# f28p551x_adc_regs register map
Vendor: Texas Instruments
Peripheral module from a debugger description file (folder C2000).
Address unit: 16 bits
Registers are 16-bit, read-write, no defined reset value unless marked. A register's access mark holds for its fields unless they carry their own. Offsets are as the file gives them; lines under a group give offsets from that group; [hi:lo] are bit positions; {n}, {i} and the like mark numbered series; 'fields as' and 'values as' point back to an identical list; <NAME> marks a mode.

## ADC_REGS — ADC Registers
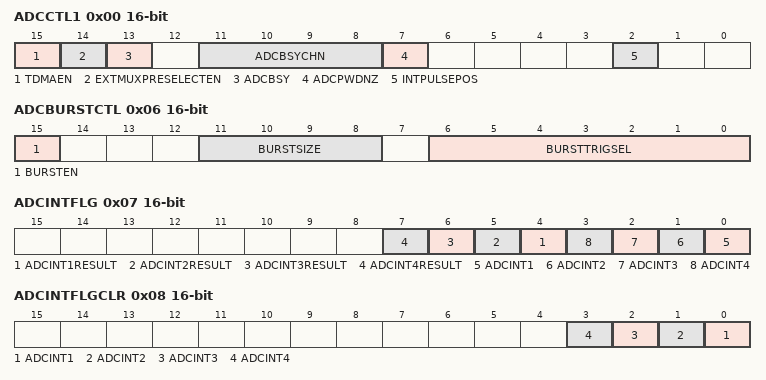
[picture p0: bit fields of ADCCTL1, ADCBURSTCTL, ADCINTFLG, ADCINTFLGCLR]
0x00 ADCCTL1 access per field — ADC Control 1 Register
  [15] TDMAEN rw — Enable Alternate DMA Timings
  [14] EXTMUXPRESELECTEN rw — External Mux Preselect Enable
  [13] ADCBSY ro — ADC Busy
  [11:8] ADCBSYCHN ro — ADC Busy Channel
  [7] ADCPWDNZ rw — ADC Power Down
  [2] INTPULSEPOS rw — ADC Interrupt Pulse Position
0x01 ADCCTL2 — ADC Control 2 Register
  [3:0] PRESCALE — ADC Clock Prescaler
0x06 ADCBURSTCTL — ADC Burst Control Register
  [15] BURSTEN — SOC Burst Mode Enable
  [11:8] BURSTSIZE — SOC Burst Size Select
  [6:0] BURSTTRIGSEL — SOC Burst Trigger Source Select
0x07 ADCINTFLG ro — ADC Interrupt Flag Register
  [n+3] ADCINT{n}RESULT (n=1..4) — ADC Interrupt {n} Results Ready
  [n-1] ADCINT{n} (n=1..4) — ADC Interrupt {n} Flag
0x08 ADCINTFLGCLR — ADC Interrupt Flag Clear Register
  [n-1] ADCINT{n} (n=1..4) — ADC Interrupt {n} Flag Clear
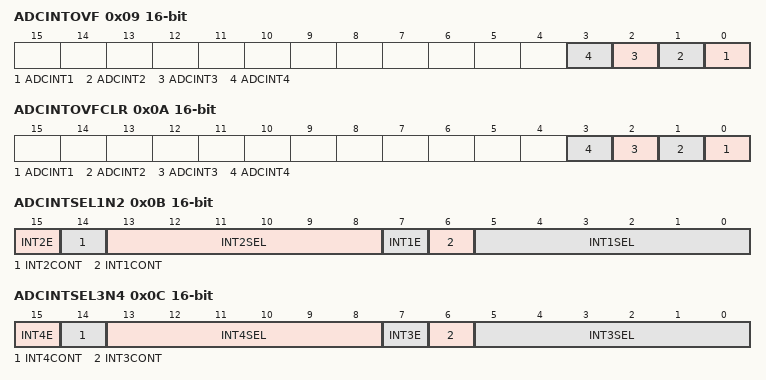
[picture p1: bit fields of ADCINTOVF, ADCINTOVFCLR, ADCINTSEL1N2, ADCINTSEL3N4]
0x09 ADCINTOVF ro — ADC Interrupt Overflow Register
  [n-1] ADCINT{n} (n=1..4) — ADC Interrupt {n} Overflow Flags
0x0A ADCINTOVFCLR — ADC Interrupt Overflow Clear Register
  [n-1] ADCINT{n} (n=1..4) — ADC Interrupt {n} Overflow Clear Bits
0x0B ADCINTSEL1N2 — ADC Interrupt 1 and 2 Selection Register
  [15] INT2E — ADCINT2 Interrupt Enable
  [14] INT2CONT — ADCINT2 Continue to Interrupt Mode
  [13:8] INT2SEL — ADCINT2 EOC Source Select
  [7] INT1E — ADCINT1 Interrupt Enable
  [6] INT1CONT — ADCINT1 Continue to Interrupt Mode
  [5:0] INT1SEL — ADCINT1 EOC Source Select
0x0C ADCINTSEL3N4 — ADC Interrupt 3 and 4 Selection Register
  [15] INT4E — ADCINT4 Interrupt Enable
  [14] INT4CONT — ADCINT4 Continue to Interrupt Mode
  [13:8] INT4SEL — ADCINT4 EOC Source Select
  [7] INT3E — ADCINT3 Interrupt Enable
  [6] INT3CONT — ADCINT3 Continue to Interrupt Mode
  [5:0] INT3SEL — ADCINT3 EOC Source Select
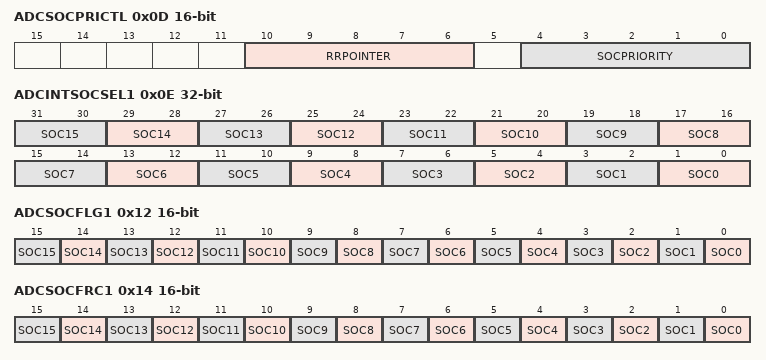
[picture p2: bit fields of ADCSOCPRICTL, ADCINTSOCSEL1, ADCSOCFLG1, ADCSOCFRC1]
0x0D ADCSOCPRICTL access per field — ADC SOC Priority Control Register
  [10:6] RRPOINTER ro — Round Robin Pointer
  [4:0] SOCPRIORITY rw
0x0E ADCINTSOCSEL1 32-bit — ADC Interrupt SOC Selection 1 Register
  [2n+1:2n] SOC{n} (n=0..15) — SOC{n} ADC Interrupt Trigger Select
0x12 ADCSOCFLG1 ro — ADC SOC Flag 1 Register
  [n] SOC{n} (n=0..15) — SOC{n} Start of Conversion Flag
0x14 ADCSOCFRC1 — ADC SOC Force 1 Register
  [n] SOC{n} (n=0..15) — SOC{n} Force Start of Conversion Bit
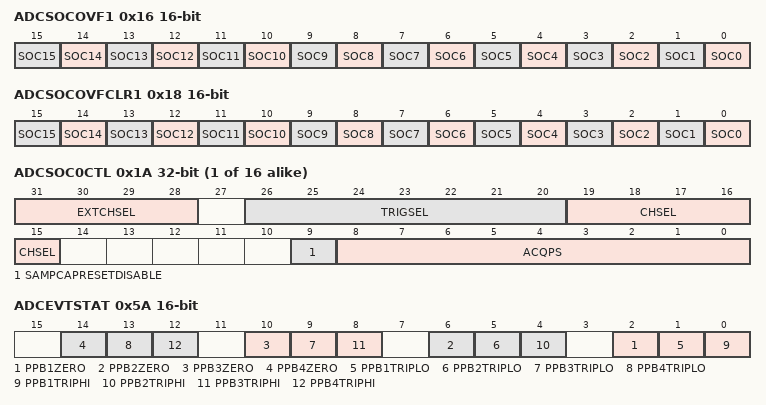
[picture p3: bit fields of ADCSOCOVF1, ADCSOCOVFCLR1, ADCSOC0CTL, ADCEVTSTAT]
0x16 ADCSOCOVF1 ro — ADC SOC Overflow 1 Register
  [n] SOC{n} (n=0..15) — SOC{n} Start of Conversion Overflow Flag
0x18 ADCSOCOVFCLR1 — ADC SOC Overflow Clear 1 Register
  [n] SOC{n} (n=0..15) — SOC{n} Clear Start of Conversion Overflow Bit
{0x1A+2i} ADCSOC{i}CTL 32-bit (i=0..15) — ADC SOC{i} Control Register
  [31:28] EXTCHSEL — SOC{i} External Channel Mux Select
  [26:20] TRIGSEL — SOC{i} Trigger Source Select
  [19:15] CHSEL — SOC{i} Channel Select
  [9] SAMPCAPRESETDISABLE — SOC{i} Sample Cap Reset Select
  [8:0] ACQPS — SOC{i} Acquisition Prescale
0x5A ADCEVTSTAT ro — ADC Event Status Register
  [4n-2] PPB{n}ZERO (n=1..4) — Post Processing Block {n} Zero Crossing Flag
  [4n-3] PPB{n}TRIPLO (n=1..4) — Post Processing Block {n} Trip Low Flag
  [4n-4] PPB{n}TRIPHI (n=1..4) — Post Processing Block {n} Trip High Flag
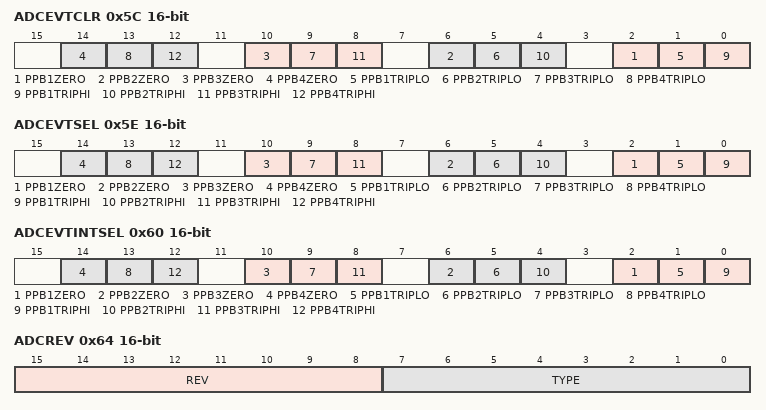
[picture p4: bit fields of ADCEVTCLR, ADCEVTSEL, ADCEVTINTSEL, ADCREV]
0x5C ADCEVTCLR — ADC Event Clear Register
  [4n-2] PPB{n}ZERO (n=1..4) — Post Processing Block {n} Zero Crossing Clear
  [4n-3] PPB{n}TRIPLO (n=1..4) — Post Processing Block {n} Trip Low Clear
  [4n-4] PPB{n}TRIPHI (n=1..4) — Post Processing Block {n} Trip High Clear
0x5E ADCEVTSEL — ADC Event Selection Register
  [4n-2] PPB{n}ZERO (n=1..4) — Post Processing Block {n} Zero Crossing Event Enable
  [4n-3] PPB{n}TRIPLO (n=1..4) — Post Processing Block {n} Trip Low Event Enable
  [4n-4] PPB{n}TRIPHI (n=1..4) — Post Processing Block {n} Trip High Event Enable
0x60 ADCEVTINTSEL — ADC Event Interrupt Selection Register
  [4n-2] PPB{n}ZERO (n=1..4) — Post Processing Block {n} Zero Crossing Interrupt Enable
  [4n-3] PPB{n}TRIPLO (n=1..4) — Post Processing Block {n} Trip Low Interrupt Enable
  [4n-4] PPB{n}TRIPHI (n=1..4) — Post Processing Block {n} Trip High Interrupt Enable
0x63 ADCCOUNTER ro
  [11:0] FREECOUNT — ADC Free Running Counter Value
0x64 ADCREV ro — ADC Revision Register
  [15:8] REV — ADC Revision
  [7:0] TYPE — ADC Type
0x65 ADCOFFTRIM — ADC Offset Trim Register
  [11:0] OFFTRIM — ADC Offset Trim
0x66 ADCCONFIG2 32-bit — ADC Config Register Upper 32 bits
  [1:0] TESTANA1_CONFIG — TESTANA1 ADC Configuration
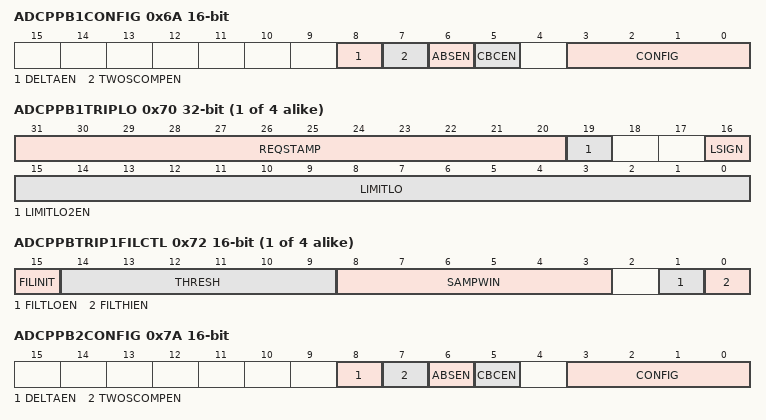
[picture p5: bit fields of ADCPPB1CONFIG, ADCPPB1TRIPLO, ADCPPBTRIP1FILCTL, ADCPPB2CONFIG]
0x6A ADCPPB1CONFIG — ADC PPB{#} Config Register
  [8] DELTAEN — ADC Post Processing Block 1 Last Sample Delta Enable
  [7] TWOSCOMPEN — ADC Post Processing Block 1 Two's Complement Enable
  [6] ABSEN — ADC Post Processing Block 1 Absolute Enable
  [5] CBCEN — Cycle By Cycle Enable
  [3:0] CONFIG — ADC Post Processing Block 1 Configuration
{0x5B+0x10*i} ADCPPB{i}STAMP ro (i=1..4) — ADC PPB{i} Sample Delay Time Stamp Register
  [11:0] DLYSTAMP — ADC Post Processing Block {i} Delay Time Stamp
{0x5C+0x10*i} ADCPPB{i}OFFCAL (i=1..4) — ADC PPB{i} Offset Calibration Register
  [9:0] OFFCAL — ADC Post Processing Block Offset Correction
{0x5D+0x10*i} ADCPPB{i}OFFREF (i=1..4) — ADC PPB{i} Offset Reference Register
  [15:0] OFFREF — ADC Post Processing Block {i} Offset Reference
{0x5E+0x10*i} ADCPPB{i}TRIPHI 32-bit (i=1..4) — ADC PPB{i} Trip High Register
  [23:0] LIMITHI — ADC Post Processing Block {i} Trip High Limit
{0x60+0x10*i} ADCPPB{i}TRIPLO 32-bit access per field (i=1..4) — ADC PPB{i} Trip Low/Trigger Time Stamp Register
  [31:20] REQSTAMP ro — ADC Post Processing Block {i} Request Time Stamp
  [19] LIMITLO2EN rw — Extended Low Limit 2 Enable
  [16] LSIGN rw — Low Limit Sign Bit
  [15:0] LIMITLO rw — ADC Post Processing Block {i} Trip Low Limit
{0x62+0x10*i} ADCPPBTRIP{i}FILCTL (i=1..4) — ADCEVT{i} Trip High Filter Control Register
  [15] FILINIT — Filter Initialization Bit
  [14:9] THRESH — Majority Voting Threshold
  [8:3] SAMPWIN — Sample Window
  [1] FILTLOEN — ADCPPB{i} TRIPLO Filter Enable
  [0] FILTHIEN — ADCPPB{i} TRIPHI Filter Enable
{0x64+0x10*i} ADCPPBTRIP{i}FILCLKCTL 32-bit (i=1..4) — ADCEVT{i} Trip High Filter Prescale Control Register
  [15:0] CLKPRESCALE — Filter Clock Prescale
0x7A ADCPPB2CONFIG — ADC PPB{#} Config Register
  [8] DELTAEN — ADC Post Processing Block 2 Last Sample Delta Enable
  [7] TWOSCOMPEN — ADC Post Processing Block 2 Two's Complement Enable
  [6] ABSEN — ADC Post Processing Block 2 Absolute Enable
  [5] CBCEN — Cycle By Cycle Enable
  [3:0] CONFIG — ADC Post Processing Block 2 Configuration
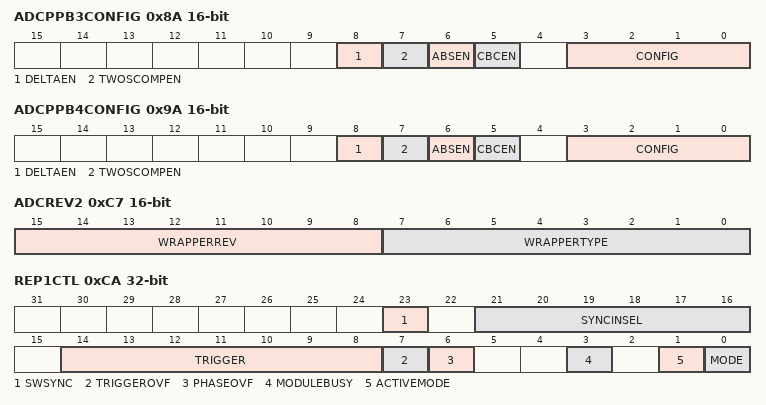
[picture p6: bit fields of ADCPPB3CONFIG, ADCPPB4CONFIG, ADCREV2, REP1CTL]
0x8A ADCPPB3CONFIG — ADC PPB{#} Config Register
  [8] DELTAEN — ADC Post Processing Block 3 Last Sample Delta Enable
  [7] TWOSCOMPEN — ADC Post Processing Block 3 Two's Complement Enable
  [6] ABSEN — ADC Post Processing Block 3 Absolute Enable
  [5] CBCEN — Cycle By Cycle Enable
  [3:0] CONFIG — ADC Post Processing Block 3 Configuration
0x9A ADCPPB4CONFIG — ADC PPB{#} Config Register
  [8] DELTAEN — ADC Post Processing Block 4 Last Sample Delta Enable
  [7] TWOSCOMPEN — ADC Post Processing Block 4 Two's Complement Enable
  [6] ABSEN — ADC Post Processing Block 4 Absolute Enable
  [5] CBCEN — Cycle By Cycle Enable
  [3:0] CONFIG — ADC Post Processing Block 4 Configuration
0xB9 ADCINTCYCLE — ADC Early Interrupt Generation Cycle
  [15:0] DELAY — Delay from ADCSOC fall edge to early interrupt generation.
{0xB8+2i} ADCINLTRIM{i} 32-bit (i=1..6) — ADC Linearity Trim {i} Register
  [31:0] INLTRIM{32i-1}TO{32i-32} — ADC Linearity Trim Bits {32i-1}-{32i-32}
0xC7 ADCREV2 ro — ADC Wrapper Revision Register
  [15:8] WRAPPERREV — ADC Wrapper Revision
  [7:0] WRAPPERTYPE — ADC Wrapper Type
0xCA REP1CTL 32-bit access per field — ADC Trigger Repeater 1 Control Register
  [23] SWSYNC rw — ADC Trigger Repeater 1 Software Sync.
  [21:16] SYNCINSEL rw — ADC Trigger Repeater 1 Sync. In Select
  [14:8] TRIGGER rw — ADC Trigger Repeater 1 Trigger Select
  [7] TRIGGEROVF rw — ADC Trigger Repeater 1 Oversampled Trigger Overflow
  [6] PHASEOVF rw — ADC Trigger Repeater 1 Phase Delay Overflow
  [3] MODULEBUSY ro — ADC Trigger Repeater 1 Module Busy
  [1] ACTIVEMODE ro — ADC Trigger Repeater 1 Active Mode
  [0] MODE rw — ADC Trigger Repeater 1 Mode Select
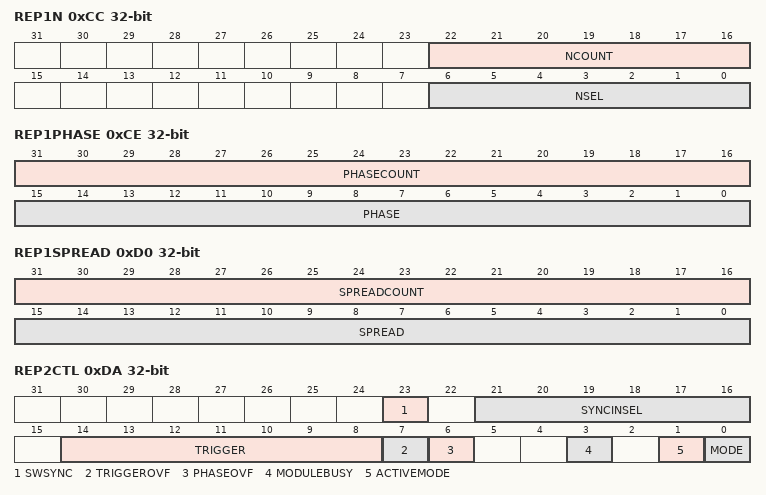
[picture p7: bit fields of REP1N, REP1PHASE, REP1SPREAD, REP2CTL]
0xCC REP1N 32-bit access per field — ADC Trigger Repeater 1 N Select Register
  [22:16] NCOUNT ro — ADC Trigger Repeater 1 Trigger Counter
  [6:0] NSEL rw — ADC Trigger Repeater 1 Trigger Number Selection
0xCE REP1PHASE 32-bit access per field — ADC Trigger Repeater 1 Phase Select Register
  [31:16] PHASECOUNT ro — ADC Trigger Repeater 1 Phase Delay Status
  [15:0] PHASE rw — ADC Trigger Repeater 1 Phase Delay Configuration
0xD0 REP1SPREAD 32-bit access per field — ADC Trigger Repeater 1 Spread Select Register
  [31:16] SPREADCOUNT ro — ADC Trigger Repeater 1 Spread Delay Status
  [15:0] SPREAD rw — ADC Trigger Repeater 1 Spread Delay Configuration
0xD2 REP1FRC — ADC Trigger Repeater 1 Software Force Register
  [0] SWFRC — ADC Trigger Repeater 1 Software Force
0xDA REP2CTL 32-bit access per field — ADC Trigger Repeater 2 Control Register
  [23] SWSYNC rw — ADC Trigger Repeater 2 Software Sync.
  [21:16] SYNCINSEL rw — ADC Trigger Repeater 2 Sync. In Select
  [14:8] TRIGGER rw — ADC Trigger Repeater 2 Trigger Select
  [7] TRIGGEROVF rw — ADC Trigger Repeater 2 Oversampled Trigger Overflow
  [6] PHASEOVF rw — ADC Trigger Repeater 2 Phase Delay Overflow
  [3] MODULEBUSY ro — ADC Trigger Repeater 2 Module Busy
  [1] ACTIVEMODE ro — ADC Trigger Repeater 2 Active Mode
  [0] MODE rw — ADC Trigger Repeater 2 Mode Select
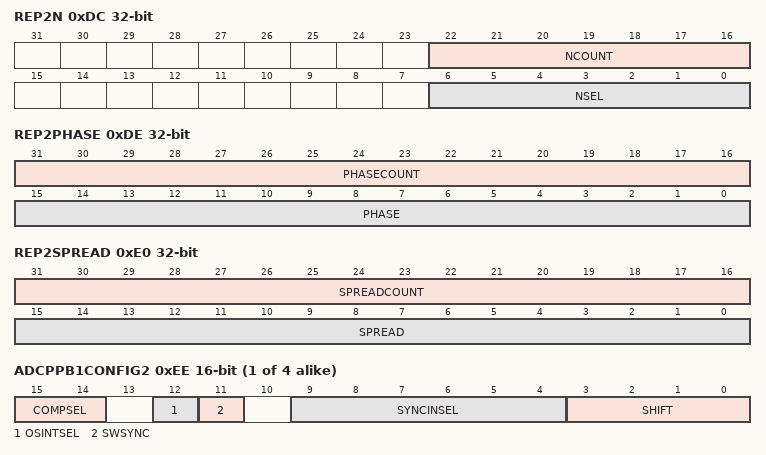
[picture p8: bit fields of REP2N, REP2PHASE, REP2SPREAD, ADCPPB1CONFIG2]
0xDC REP2N 32-bit access per field — ADC Trigger Repeater 2 N Select Register
  [22:16] NCOUNT ro — ADC Trigger Repeater 2 Trigger Counter
  [6:0] NSEL rw — ADC Trigger Repeater 2 Trigger Number Selection
0xDE REP2PHASE 32-bit access per field — ADC Trigger Repeater 2 Phase Select Register
  [31:16] PHASECOUNT ro — ADC Trigger Repeater 2 Phase Delay Status
  [15:0] PHASE rw — ADC Trigger Repeater 2 Phase Delay Configuration
0xE0 REP2SPREAD 32-bit access per field — ADC Trigger Repeater 2 Spread Select Register
  [31:16] SPREADCOUNT ro — ADC Trigger Repeater 2 Spread Delay Status
  [15:0] SPREAD rw — ADC Trigger Repeater 2 Spread Delay Configuration
0xE2 REP2FRC — ADC Trigger Repeater 2 Software Force Register
  [0] SWFRC — ADC Trigger Repeater 2 Software Force
{0xD0+0x1A*i} ADCPPB{i}LIMIT (i=1..4) — ADC PPB{i}Conversion Count Limit Register
  [9:0] LIMIT — Post Processing Block {i} Limit
{0xD2+0x1A*i} ADCPPBP{i}PCOUNT ro (i=1..4) — ADC PPB{i} Partial Conversion Count Register
  [9:0] PCOUNT — Post Processing Block {i} Partial Count
{0xD4+0x1A*i} ADCPPB{i}CONFIG2 (i=1..4) — ADC PPB{i} Sum Shift Register
  [15:14] COMPSEL — Post Processing Block {i} Compare Source Select
  [12] OSINTSEL — Post Processing Block {i} Interrupt Source Select
  [11] SWSYNC — Post Processing Block {i} Software Force Sync.
  [9:4] SYNCINSEL — Post Processing Block {i} Sync. Input Select
  [3:0] SHIFT — Post Processing Block {i} Right Shift
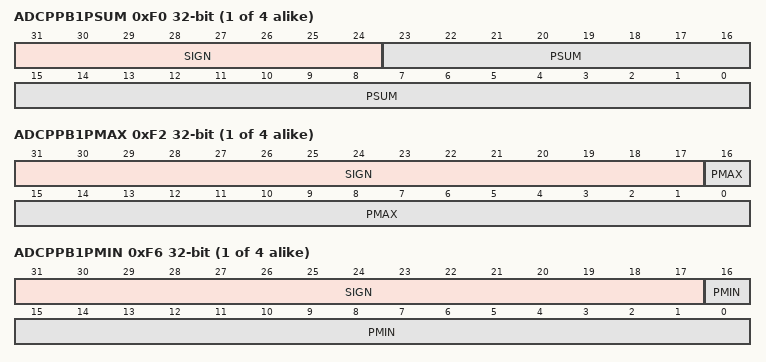
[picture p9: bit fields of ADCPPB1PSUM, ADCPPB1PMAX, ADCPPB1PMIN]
{0xD6+0x1A*i} ADCPPB{i}PSUM 32-bit ro (i=1..4) — ADC PPB{i} Partial Sum Register
  [31:24] SIGN — Sign Extended Bits
  [23:0] PSUM — Post Processing Block {i} Oversampling Partial Sum
{0xD8+0x1A*i} ADCPPB{i}PMAX 32-bit ro (i=1..4) — ADC PPB{i} Partial Max Register
  [31:17] SIGN — Sign Extended Bits
  [16:0] PMAX — Post Processing Block {i} Oversampling Partial Max
{0xDA+0x1A*i} ADCPPB{i}PMAXI ro (i=1..4) — ADC PPB{i} Partial Max Index Register
  [9:0] PMAXI — Post Processing Block {i} Oversampling Partial Index of Max
{0xDC+0x1A*i} ADCPPB{i}PMIN 32-bit ro (i=1..4) — ADC PPB{i} Partial MIN Register
  [31:17] SIGN — Sign Extended Bits
  [16:0] PMIN — Post Processing Block {i} Oversampling Partial Min
{0xDE+0x1A*i} ADCPPB{i}PMINI ro (i=1..4) — ADC PPB{i} Partial Min Index Register
  [9:0] PMINI — Post Processing Block {i} Oversampling Partial Index of Min
{0xE0+0x1A*i} ADCPPB{i}TRIPLO2 32-bit (i=1..4) — ADC PPB{i} Extended Trip Low Register
  [23:0] LIMITLO — ADC Post Processing Block {i} Trip Low Limit
